# f28004x_erad_hwbp_regs register map
Vendor: Texas Instruments
Peripheral module from a debugger description file (folder C2000).
Address unit: 16 bits
Registers are 16-bit, read-write, no defined reset value unless marked. A register's access mark holds for its fields unless they carry their own. Offsets are as the file gives them; lines under a group give offsets from that group; [hi:lo] are bit positions; {n}, {i} and the like mark numbered series; 'fields as' and 'values as' point back to an identical list; <NAME> marks a mode.

## ERAD_HWBP_REGS — ERAD HWBP Registers
0x00 HWBP_MASK 32-bit
  [31:0] MASK — Address mask register
0x02 HWBP_REF 32-bit — HWBP Reference Register
  [31:0] REF — Address reference register
0x04 HWBP_CLEAR
  [0] EVENT_CLR — Event Clear register
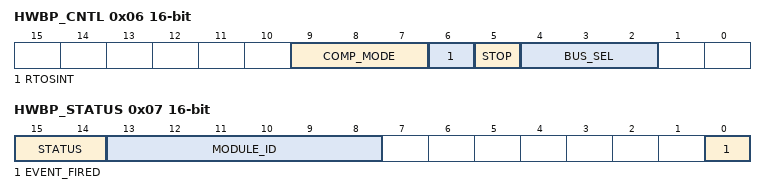
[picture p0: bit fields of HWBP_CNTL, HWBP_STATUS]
0x06 HWBP_CNTL — HWBP Control Register
  [9:7] COMP_MODE — Compare mode
  [6] RTOSINT — RTOSINT bit
  [5] STOP — Stop bit (Halt/No Halt of CPU)
  [4:2] BUS_SEL — Bus select bits
0x07 HWBP_STATUS ro
  [15:14] STATUS — Status bits
  [13:8] MODULE_ID — Identification bits
  [0] EVENT_FIRED — HWBP Event Fired bits
